# ior7f701503 register map
Registers are 8-bit, access not given, no defined reset value unless marked. A register's access mark holds for its fields unless they carry their own. Addresses are absolute; registers are grouped by the start of their names; [hi:lo] are bit positions; {n}, {i} and the like mark numbered series.

## SFR (part 1 of 4)
0x10020004 FLXA0FROC 32-bit
0x10020004 FLXA0FROCL 16-bit
0x10020004 FLXA0FROCLL
0x10020006 FLXA0FROCH 16-bit
0x10020006 FLXA0FROCHL
0x1002000C FLXA0FROS 32-bit
0x1002000C FLXA0FROSL 16-bit ro
0x1002000C FLXA0FROSLL ro
0x1002000E FLXA0FROSH 16-bit
0x1002000E FLXA0FROSHL
0x1002001C FLXA0FRLCK 32-bit
0x1002001C FLXA0FRLCKL 16-bit
0x1002001C FLXA0FRLCKLL
0x1002001D FLXA0FRLCKLH
0x10020020 FLXA0FREIR 32-bit
0x10020020 FLXA0FREIRL 16-bit
0x10020020 FLXA0FREIRLL
0x10020021 FLXA0FREIRLH
0x10020022 FLXA0FREIRH 16-bit
0x10020022 FLXA0FREIRHL
0x10020023 FLXA0FREIRHH
0x10020024 FLXA0FRSIR 32-bit
0x10020024 FLXA0FRSIRL 16-bit
0x10020024 FLXA0FRSIRLL
0x10020025 FLXA0FRSIRLH
0x10020026 FLXA0FRSIRH 16-bit
0x10020026 FLXA0FRSIRHL
0x10020027 FLXA0FRSIRHH
0x10020028 FLXA0FREILS 32-bit
0x10020028 FLXA0FREILSL 16-bit
0x10020028 FLXA0FREILSLL
0x10020029 FLXA0FREILSLH
0x1002002A FLXA0FREILSH 16-bit
0x1002002A FLXA0FREILSHL
0x1002002B FLXA0FREILSHH
0x1002002C FLXA0FRSILS 32-bit
0x1002002C FLXA0FRSILSL 16-bit
0x1002002C FLXA0FRSILSLL
0x1002002D FLXA0FRSILSLH
0x1002002E FLXA0FRSILSH 16-bit
0x1002002E FLXA0FRSILSHL
0x1002002F FLXA0FRSILSHH
0x10020030 FLXA0FREIES 32-bit
0x10020030 FLXA0FREIESL 16-bit
0x10020030 FLXA0FREIESLL
0x10020031 FLXA0FREIESLH
0x10020032 FLXA0FREIESH 16-bit
0x10020032 FLXA0FREIESHL
0x10020033 FLXA0FREIESHH
0x10020034 FLXA0FREIER 32-bit
0x10020034 FLXA0FREIERL 16-bit
0x10020034 FLXA0FREIERLL
0x10020035 FLXA0FREIERLH
0x10020036 FLXA0FREIERH 16-bit
0x10020036 FLXA0FREIERHL
0x10020037 FLXA0FREIERHH
0x10020038 FLXA0FRSIES 32-bit
0x10020038 FLXA0FRSIESL 16-bit
0x10020038 FLXA0FRSIESLL
0x10020039 FLXA0FRSIESLH
0x1002003A FLXA0FRSIESH 16-bit
0x1002003A FLXA0FRSIESHL
0x1002003B FLXA0FRSIESHH
0x1002003C FLXA0FRSIER 32-bit
0x1002003C FLXA0FRSIERL 16-bit
0x1002003C FLXA0FRSIERLL
0x1002003D FLXA0FRSIERLH
0x1002003E FLXA0FRSIERH 16-bit
0x1002003E FLXA0FRSIERHL
0x1002003F FLXA0FRSIERHH
0x10020040 FLXA0FRILE 32-bit
0x10020040 FLXA0FRILEL 16-bit
0x10020040 FLXA0FRILELL
0x10020044 FLXA0FRT0C 32-bit
0x10020044 FLXA0FRT0CL 16-bit
0x10020044 FLXA0FRT0CLL
0x10020045 FLXA0FRT0CLH
0x10020046 FLXA0FRT0CH 16-bit
0x10020046 FLXA0FRT0CHL
0x10020047 FLXA0FRT0CHH
0x10020048 FLXA0FRT1C 32-bit
0x10020048 FLXA0FRT1CL 16-bit
0x10020048 FLXA0FRT1CLL
0x1002004A FLXA0FRT1CH 16-bit
0x1002004A FLXA0FRT1CHL
0x1002004B FLXA0FRT1CHH
0x1002004C FLXA0FRSTPW1 32-bit
0x1002004C FLXA0FRSTPW1L 16-bit
0x1002004C FLXA0FRSTPW1LL
0x1002004D FLXA0FRSTPW1LH ro
0x1002004E FLXA0FRSTPW1H 16-bit ro
0x1002004E FLXA0FRSTPW1HL ro
0x1002004F FLXA0FRSTPW1HH ro
0x10020050 FLXA0FRSTPW2 32-bit ro
0x10020050 FLXA0FRSTPW2L 16-bit ro
0x10020050 FLXA0FRSTPW2LL ro
0x10020051 FLXA0FRSTPW2LH ro
0x10020052 FLXA0FRSTPW2H 16-bit ro
0x10020052 FLXA0FRSTPW2HL ro
0x10020053 FLXA0FRSTPW2HH ro
{0x1002007C+4i} FLXA0FRSUCC{i} 32-bit (i=1..3)
{0x1002007C+4i} FLXA0FRSUCC{i}L 16-bit (i=1..3)
{0x1002007C+4i} FLXA0FRSUCC{i}LL (i=1..3)
0x10020081 FLXA0FRSUCC1LH
0x10020082 FLXA0FRSUCC1H 16-bit
0x10020082 FLXA0FRSUCC1HL
0x10020083 FLXA0FRSUCC1HH
0x10020085 FLXA0FRSUCC2LH
0x10020086 FLXA0FRSUCC2H 16-bit
0x10020086 FLXA0FRSUCC2HL
0x10020087 FLXA0FRSUCC2HH
0x1002008C FLXA0FRNEMC 32-bit
0x1002008C FLXA0FRNEMCL 16-bit
0x1002008C FLXA0FRNEMCLL
0x10020090 FLXA0FRPRTC1 32-bit
0x10020090 FLXA0FRPRTC1L 16-bit
0x10020090 FLXA0FRPRTC1LL
0x10020091 FLXA0FRPRTC1LH
0x10020092 FLXA0FRPRTC1H 16-bit
0x10020092 FLXA0FRPRTC1HL
0x10020093 FLXA0FRPRTC1HH
0x10020094 FLXA0FRPRTC2 32-bit
0x10020094 FLXA0FRPRTC2L 16-bit
0x10020094 FLXA0FRPRTC2LL
0x10020095 FLXA0FRPRTC2LH
0x10020096 FLXA0FRPRTC2H 16-bit
0x10020096 FLXA0FRPRTC2HL
0x10020097 FLXA0FRPRTC2HH
0x10020098 FLXA0FRMHDC 32-bit
0x10020098 FLXA0FRMHDCL 16-bit
0x10020098 FLXA0FRMHDCLL
0x1002009A FLXA0FRMHDCH 16-bit
0x1002009A FLXA0FRMHDCHL
0x1002009B FLXA0FRMHDCHH
{0x1002009C+4i} FLXA0FRGTUC{i} 32-bit (i=1..11)
{0x1002009C+4i} FLXA0FRGTUC{i}L 16-bit (i=1..11)
{0x1002009C+4i} FLXA0FRGTUC{i}LL (i=1..11)
{0x1002009D+4i} FLXA0FRGTUC{i}LH (i=1..7)
{0x1002009E+4i} FLXA0FRGTUC{i}H 16-bit (i=1..11)
{0x1002009E+4i} FLXA0FRGTUC{i}HL (i=1..11)
{0x1002009F+4i} FLXA0FRGTUC{i}HH (i=3..8)
{0x1002009D+4i} FLXA0FRGTUC{i}LH (i=9..11)
0x100200C7 FLXA0FRGTUC10HH
0x100200CB FLXA0FRGTUC11HH
0x10020100 FLXA0FRCCSV 32-bit ro
0x10020100 FLXA0FRCCSVL 16-bit ro
0x10020100 FLXA0FRCCSVLL ro
0x10020101 FLXA0FRCCSVLH ro
0x10020102 FLXA0FRCCSVH 16-bit ro
0x10020102 FLXA0FRCCSVHL ro
0x10020103 FLXA0FRCCSVHH ro
0x10020104 FLXA0FRCCEV 32-bit ro
0x10020104 FLXA0FRCCEVL 16-bit ro
0x10020104 FLXA0FRCCEVLL ro
0x10020105 FLXA0FRCCEVLH ro
0x10020110 FLXA0FRSCV 32-bit ro
0x10020110 FLXA0FRSCVL 16-bit ro
0x10020110 FLXA0FRSCVLL ro
0x10020111 FLXA0FRSCVLH ro
0x10020112 FLXA0FRSCVH 16-bit ro
0x10020112 FLXA0FRSCVHL ro
0x10020113 FLXA0FRSCVHH ro
0x10020114 FLXA0FRMTCCV 32-bit ro
0x10020114 FLXA0FRMTCCVL 16-bit ro
0x10020114 FLXA0FRMTCCVLL ro
0x10020115 FLXA0FRMTCCVLH ro
0x10020116 FLXA0FRMTCCVH 16-bit ro
0x10020116 FLXA0FRMTCCVHL ro
0x10020118 FLXA0FRRCV 32-bit ro
0x10020118 FLXA0FRRCVL 16-bit ro
0x10020118 FLXA0FRRCVLL ro
0x10020119 FLXA0FRRCVLH ro
0x1002011C FLXA0FROCV 32-bit ro
0x1002011C FLXA0FROCVL 16-bit ro
0x1002011C FLXA0FROCVLL ro
0x1002011D FLXA0FROCVLH ro
0x1002011E FLXA0FROCVH 16-bit ro
0x1002011E FLXA0FROCVHL ro
0x10020120 FLXA0FRSFS 32-bit ro
0x10020120 FLXA0FRSFSL 16-bit ro
0x10020120 FLXA0FRSFSLL ro
0x10020121 FLXA0FRSFSLH ro
0x10020122 FLXA0FRSFSH 16-bit ro
0x10020122 FLXA0FRSFSHL ro
0x10020124 FLXA0FRSWNIT 32-bit ro
0x10020124 FLXA0FRSWNITL 16-bit ro
0x10020124 FLXA0FRSWNITLL ro
0x10020125 FLXA0FRSWNITLH ro
0x10020128 FLXA0FRACS 32-bit
0x10020128 FLXA0FRACSL 16-bit
0x10020128 FLXA0FRACSLL
0x10020129 FLXA0FRACSLH
{0x1002012C+4i} FLXA0FRESID{i} 32-bit ro (i=1..15)
{0x1002012C+4i} FLXA0FRESID{i}L 16-bit ro (i=1..15)
{0x1002012C+4i} FLXA0FRESID{i}LL ro (i=1..15)
{0x1002012D+4i} FLXA0FRESID{i}LH ro (i=1..15)
{0x1002016C+4i} FLXA0FROSID{i} 32-bit ro (i=1..15)
{0x1002016C+4i} FLXA0FROSID{i}L 16-bit ro (i=1..15)
{0x1002016C+4i} FLXA0FROSID{i}LL ro (i=1..15)
{0x1002016D+4i} FLXA0FROSID{i}LH ro (i=1..15)
{0x100201AC+4i} FLXA0FRNMV{i} 32-bit ro (i=1..3)
{0x100201AC+4i} FLXA0FRNMV{i}L 16-bit ro (i=1..3)
{0x100201AC+4i} FLXA0FRNMV{i}LL ro (i=1..3)
{0x100201AD+4i} FLXA0FRNMV{i}LH ro (i=1..3)
{0x100201AE+4i} FLXA0FRNMV{i}H 16-bit ro (i=1..3)
{0x100201AE+4i} FLXA0FRNMV{i}HL ro (i=1..3)
{0x100201AF+4i} FLXA0FRNMV{i}HH ro (i=1..3)
0x10020300 FLXA0FRMRC 32-bit
0x10020300 FLXA0FRMRCL 16-bit
0x10020300 FLXA0FRMRCLL
0x10020301 FLXA0FRMRCLH
0x10020302 FLXA0FRMRCH 16-bit
0x10020302 FLXA0FRMRCHL
0x10020303 FLXA0FRMRCHH
0x10020304 FLXA0FRFRF 32-bit
0x10020304 FLXA0FRFRFL 16-bit
0x10020304 FLXA0FRFRFLL
0x10020305 FLXA0FRFRFLH
0x10020306 FLXA0FRFRFH 16-bit
0x10020306 FLXA0FRFRFHL
0x10020307 FLXA0FRFRFHH
0x10020308 FLXA0FRFRFM 32-bit
0x10020308 FLXA0FRFRFML 16-bit
0x10020308 FLXA0FRFRFMLL
0x10020309 FLXA0FRFRFMLH
0x1002030C FLXA0FRFCL 32-bit
0x1002030C FLXA0FRFCLL 16-bit
0x1002030C FLXA0FRFCLLL
0x10020310 FLXA0FRMHDS 32-bit
0x10020310 FLXA0FRMHDSL 16-bit
0x10020310 FLXA0FRMHDSLL
0x10020311 FLXA0FRMHDSLH ro
0x10020312 FLXA0FRMHDSH 16-bit ro
0x10020312 FLXA0FRMHDSHL ro
0x10020313 FLXA0FRMHDSHH ro
0x10020314 FLXA0FRLDTS 32-bit ro
0x10020314 FLXA0FRLDTSL 16-bit ro
0x10020314 FLXA0FRLDTSLL ro
0x10020315 FLXA0FRLDTSLH ro
0x10020316 FLXA0FRLDTSH 16-bit ro
0x10020316 FLXA0FRLDTSHL ro
0x10020317 FLXA0FRLDTSHH ro
0x10020318 FLXA0FRFSR 32-bit ro
0x10020318 FLXA0FRFSRL 16-bit ro
0x10020318 FLXA0FRFSRLL ro
0x10020319 FLXA0FRFSRLH ro
0x1002031C FLXA0FRMHDF 32-bit
0x1002031C FLXA0FRMHDFL 16-bit
0x1002031C FLXA0FRMHDFLL
0x1002031D FLXA0FRMHDFLH
{0x1002031C+4i} FLXA0FRTXRQ{i} 32-bit ro (i=1..4)
{0x1002031C+4i} FLXA0FRTXRQ{i}L 16-bit ro (i=1..4)
{0x1002031C+4i} FLXA0FRTXRQ{i}LL ro (i=1..4)
{0x1002031D+4i} FLXA0FRTXRQ{i}LH ro (i=1..4)
{0x1002031E+4i} FLXA0FRTXRQ{i}H 16-bit ro (i=1..4)
{0x1002031E+4i} FLXA0FRTXRQ{i}HL ro (i=1..4)
{0x1002031F+4i} FLXA0FRTXRQ{i}HH ro (i=1..4)
{0x1002032C+4i} FLXA0FRNDAT{i} 32-bit ro (i=1..4)
{0x1002032C+4i} FLXA0FRNDAT{i}L 16-bit ro (i=1..4)
{0x1002032C+4i} FLXA0FRNDAT{i}LL ro (i=1..4)
{0x1002032D+4i} FLXA0FRNDAT{i}LH ro (i=1..4)
{0x1002032E+4i} FLXA0FRNDAT{i}H 16-bit ro (i=1..4)
{0x1002032E+4i} FLXA0FRNDAT{i}HL ro (i=1..4)
{0x1002032F+4i} FLXA0FRNDAT{i}HH ro (i=1..4)
{0x1002033C+4i} FLXA0FRMBSC{i} 32-bit ro (i=1..4)
{0x1002033C+4i} FLXA0FRMBSC{i}L 16-bit ro (i=1..4)
{0x1002033C+4i} FLXA0FRMBSC{i}LL ro (i=1..4)
{0x1002033D+4i} FLXA0FRMBSC{i}LH ro (i=1..4)
{0x1002033E+4i} FLXA0FRMBSC{i}H 16-bit ro (i=1..4)
{0x1002033E+4i} FLXA0FRMBSC{i}HL ro (i=1..4)
{0x1002033F+4i} FLXA0FRMBSC{i}HH ro (i=1..4)
{0x100203FC+4i} FLXA0FRWRDS{i} 32-bit (i=1..64)
{0x100203FC+4i} FLXA0FRWRDS{i}L 16-bit (i=1..64)
{0x100203FC+4i} FLXA0FRWRDS{i}LL (i=1..64)
{0x100203FD+4i} FLXA0FRWRDS{i}LH (i=1..64)
{0x100203FE+4i} FLXA0FRWRDS{i}H 16-bit (i=1..64)
{0x100203FE+4i} FLXA0FRWRDS{i}HL (i=1..64)
{0x100203FF+4i} FLXA0FRWRDS{i}HH (i=1..64)
{0x100204FC+4i} FLXA0FRWRHS{i} 32-bit (i=1..3)
{0x100204FC+4i} FLXA0FRWRHS{i}L 16-bit (i=1..3)
{0x100204FC+4i} FLXA0FRWRHS{i}LL (i=1..3)
{0x100204FD+4i} FLXA0FRWRHS{i}LH (i=1..3)
0x10020502 FLXA0FRWRHS1H 16-bit
0x10020502 FLXA0FRWRHS1HL
0x10020503 FLXA0FRWRHS1HH
0x10020506 FLXA0FRWRHS2H 16-bit
0x10020506 FLXA0FRWRHS2HL
0x10020510 FLXA0FRIBCM 32-bit
0x10020510 FLXA0FRIBCML 16-bit
0x10020510 FLXA0FRIBCMLL
0x10020512 FLXA0FRIBCMH 16-bit ro
0x10020512 FLXA0FRIBCMHL ro
0x10020514 FLXA0FRIBCR 32-bit
0x10020514 FLXA0FRIBCRL 16-bit
0x10020514 FLXA0FRIBCRLL
0x10020515 FLXA0FRIBCRLH ro
0x10020516 FLXA0FRIBCRH 16-bit ro
0x10020516 FLXA0FRIBCRHL ro
0x10020517 FLXA0FRIBCRHH ro
{0x100205FC+4i} FLXA0FRRDDS{i} 32-bit ro (i=1..64)
{0x100205FC+4i} FLXA0FRRDDS{i}L 16-bit ro (i=1..64)
{0x100205FC+4i} FLXA0FRRDDS{i}LL ro (i=1..64)
{0x100205FD+4i} FLXA0FRRDDS{i}LH ro (i=1..64)
{0x100205FE+4i} FLXA0FRRDDS{i}H 16-bit ro (i=1..64)
{0x100205FE+4i} FLXA0FRRDDS{i}HL ro (i=1..64)
{0x100205FF+4i} FLXA0FRRDDS{i}HH ro (i=1..64)
{0x100206FC+4i} FLXA0FRRDHS{i} 32-bit ro (i=1..3)
{0x100206FC+4i} FLXA0FRRDHS{i}L 16-bit ro (i=1..3)
{0x100206FC+4i} FLXA0FRRDHS{i}LL ro (i=1..3)
{0x100206FD+4i} FLXA0FRRDHS{i}LH ro (i=1..3)
{0x100206FE+4i} FLXA0FRRDHS{i}H 16-bit ro (i=1..3)
{0x100206FE+4i} FLXA0FRRDHS{i}HL ro (i=1..3)
{0x100206FF+4i} FLXA0FRRDHS{i}HH ro (i=1..3)
0x1002070C FLXA0FRMBS 32-bit ro
0x1002070C FLXA0FRMBSL 16-bit ro
0x1002070C FLXA0FRMBSLL ro
0x1002070D FLXA0FRMBSLH ro
0x1002070E FLXA0FRMBSH 16-bit ro
0x1002070E FLXA0FRMBSHL ro
0x1002070F FLXA0FRMBSHH ro
0x10020710 FLXA0FROBCM 32-bit
0x10020710 FLXA0FROBCML 16-bit
0x10020710 FLXA0FROBCMLL
0x10020712 FLXA0FROBCMH 16-bit ro
0x10020712 FLXA0FROBCMHL ro
0x10020714 FLXA0FROBCR 32-bit
0x10020714 FLXA0FROBCRL 16-bit
0x10020714 FLXA0FROBCRLL
0x10020715 FLXA0FROBCRLH
0x10020716 FLXA0FROBCRH 16-bit ro
0x10020716 FLXA0FROBCRHL ro
0x10020800 FLXA0FRITC 32-bit
0x10020800 FLXA0FRITCL 16-bit
0x10020800 FLXA0FRITCLL
0x10020801 FLXA0FRITCLH
0x10020802 FLXA0FRITCH 16-bit
0x10020802 FLXA0FRITCHL
0x10020804 FLXA0FROTC 32-bit
0x10020804 FLXA0FROTCL 16-bit
0x10020804 FLXA0FROTCLL
0x10020805 FLXA0FROTCLH
0x10020806 FLXA0FROTCH 16-bit
0x10020806 FLXA0FROTCHL
0x10020808 FLXA0FRIBA 32-bit
0x10020808 FLXA0FRIBAL 16-bit
0x10020808 FLXA0FRIBALL
0x10020809 FLXA0FRIBALH
0x1002080A FLXA0FRIBAH 16-bit
0x1002080A FLXA0FRIBAHL
0x1002080B FLXA0FRIBAHH
0x1002080C FLXA0FRFBA 32-bit
0x1002080C FLXA0FRFBAL 16-bit
0x1002080C FLXA0FRFBALL
0x1002080D FLXA0FRFBALH
0x1002080E FLXA0FRFBAH 16-bit
0x1002080E FLXA0FRFBAHL
0x1002080F FLXA0FRFBAHH
0x10020810 FLXA0FROBA 32-bit
0x10020810 FLXA0FROBAL 16-bit
0x10020810 FLXA0FROBALL
0x10020811 FLXA0FROBALH
0x10020812 FLXA0FROBAH 16-bit
0x10020812 FLXA0FROBAHL
0x10020813 FLXA0FROBAHH
0x10020814 FLXA0FRIQC 32-bit wo
0x10020814 FLXA0FRIQCL 16-bit wo
0x10020814 FLXA0FRIQCLL wo
0x10020818 FLXA0FRUIR 32-bit
0x10020818 FLXA0FRUIRL 16-bit
0x10020818 FLXA0FRUIRLL
0x1002081C FLXA0FRUOR 32-bit
0x1002081C FLXA0FRUORL 16-bit
0x1002081C FLXA0FRUORLL
0x1002081D FLXA0FRUORLH
0x10020820 FLXA0FRITS 32-bit
0x10020820 FLXA0FRITSL 16-bit
0x10020820 FLXA0FRITSLL ro
0x10020821 FLXA0FRITSLH
0x10020822 FLXA0FRITSH 16-bit ro
0x10020822 FLXA0FRITSHL ro
0x10020823 FLXA0FRITSHH ro
0x10020824 FLXA0FROTS 32-bit
0x10020824 FLXA0FROTSL 16-bit
0x10020824 FLXA0FROTSLL ro
0x10020825 FLXA0FROTSLH
0x10020826 FLXA0FROTSH 16-bit ro
0x10020826 FLXA0FROTSHL ro
0x10020827 FLXA0FROTSHH ro
0x10020828 FLXA0FRAES 32-bit
0x10020828 FLXA0FRAESL 16-bit
0x10020828 FLXA0FRAESLL ro
0x10020829 FLXA0FRAESLH
0x1002082C FLXA0FRAEA 32-bit ro
0x1002082C FLXA0FRAEAL 16-bit ro
0x1002082C FLXA0FRAEALL ro
0x1002082D FLXA0FRAEALH ro
0x1002082E FLXA0FRAEAH 16-bit ro
0x1002082E FLXA0FRAEAHL ro
0x1002082F FLXA0FRAEAHH ro
{0x10020830+4i} FLXA0FRDA{i} 32-bit (i=0..3)
{0x10020830+4i} FLXA0FRDA{i}L 16-bit (i=0..3)
{0x10020830+4i} FLXA0FRDA{i}LL (i=0..3)
{0x10020831+4i} FLXA0FRDA{i}LH (i=0..3)
{0x10020832+4i} FLXA0FRDA{i}H 16-bit (i=0..3)
{0x10020832+4i} FLXA0FRDA{i}HL (i=0..3)
{0x10020833+4i} FLXA0FRDA{i}HH (i=0..3)
0x10020840 FLXA0FRAHBC 32-bit
0x10020840 FLXA0FRAHBCL 16-bit
0x10020840 FLXA0FRAHBCLL
0x10020844 FLXA0FRT2C 32-bit
0x10020844 FLXA0FRT2CL 16-bit
0x10020844 FLXA0FRT2CLL
0x10020845 FLXA0FRT2CLH
0x10020846 FLXA0FRT2CH 16-bit
0x10020846 FLXA0FRT2CHL
0x10020847 FLXA0FRT2CHH
0x10030002 MEMC0DEC 16-bit
0x10030008 MEMC0DWC 16-bit
0x1003000C MEMC0DHC 16-bit
0x1003000E MEMC0DSC 16-bit
0x10030010 MEMC0AWC 16-bit
0x10030014 MEMC0ICC 16-bit
0x1003001A MEMC0EWC 16-bit
0xFFA00000 FLMDCNT 32-bit
0xFFA00004 FLMDPCMD 32-bit wo
0xFFA00008 FLMDPS 32-bit ro
{0xFFA08000+4i} SELFID{i} 32-bit (i=0..3)
0xFFA08010 SELFIDST 32-bit ro
0xFFA10000 FACIFPMON ro
0xFFA10010 FACIFASTAT
0xFFA10014 FACIFAEINT
0xFFA10020 FACIFAREASELC 16-bit
0xFFA10030 FACIFSADDR 32-bit
0xFFA10034 FACIFEADDR 32-bit
0xFFA10054 FACIFCURAME 16-bit
0xFFA10080 FACIFSTATR 32-bit ro
0xFFA10084 FACIFENTRYR 16-bit
0xFFA10088 FACIFPROTR 16-bit
0xFFA1008C FACIFSUINITR 16-bit
0xFFA10090 FACIFLKSTAT ro
0xFFA10094 FACIFRFSTEADR 32-bit ro
0xFFA100A0 FACIFCMDR 16-bit ro
0xFFA100B0 FACIFRAMECCR 16-bit
0xFFA100C0 FACIFPESTAT 16-bit ro
0xFFA100D0 FACIFBCCNT
0xFFA100D4 FACIFBCSTAT ro
0xFFA100D8 FACIFPSADDR 32-bit ro
0xFFA100E0 FACIFCPSR 16-bit
0xFFA100E4 FACIFPCKAR 16-bit
0xFFA10100 FACIFECCEMON 16-bit ro
0xFFA10104 FACIFECCTMD 16-bit
0xFFA10108 FACIFDMYECC 16-bit
0xFFC00000 WDTNMIF 32-bit ro
0xFFC00008 WDTNMIFC 32-bit wo
0xFFC00100 FEINTF 32-bit ro
0xFFC00104 FEINTFMSK 32-bit
0xFFC00108 FEINTFC 32-bit wo
{0xFFC10000+4i} P{i} 16-bit (i=0..2)
{0xFFC10000+4i} P{i} 16-bit (i=8..12)
0xFFC10048 P18 16-bit
0xFFC10050 P20 16-bit
0xFFC100C8 AP0 16-bit
0xFFC100CC AP1 16-bit
{0xFFC10100+4i} PSR{i} 32-bit (i=0..2)
{0xFFC10100+4i} PSR{i} 32-bit (i=8..12)
0xFFC10148 PSR18 32-bit
0xFFC10150 PSR20 32-bit
0xFFC101C8 APSR0 32-bit
0xFFC101CC APSR1 32-bit
{0xFFC10200+4i} PPR{i} 16-bit ro (i=0..2)
{0xFFC10200+4i} PPR{i} 16-bit ro (i=8..12)
0xFFC10248 PPR18 16-bit ro
0xFFC10250 PPR20 16-bit ro
0xFFC102C8 APPR0 16-bit ro
0xFFC102CC APPR1 16-bit ro
0xFFC102F0 IPPR0 16-bit ro
{0xFFC10300+4i} PM{i} 16-bit (i=0..2)
{0xFFC10300+4i} PM{i} 16-bit (i=8..12)
0xFFC10348 PM18 16-bit
0xFFC10350 PM20 16-bit
0xFFC103C8 APM0 16-bit
0xFFC103CC APM1 16-bit
{0xFFC10400+4i} PMC{i} 16-bit (i=0..2)
{0xFFC10400+4i} PMC{i} 16-bit (i=8..12)
0xFFC10448 PMC18 16-bit
0xFFC10450 PMC20 16-bit
{0xFFC10500+4i} PFC{i} 16-bit (i=0..2)
{0xFFC10500+4i} PFC{i} 16-bit (i=8..12)
0xFFC10548 PFC18 16-bit
0xFFC10550 PFC20 16-bit
0xFFC10600 PFCE0 16-bit
{0xFFC10600+4i} PFCE{i} 16-bit (i=8..12)
0xFFC10648 PFCE18 16-bit
0xFFC10650 PFCE20 16-bit
{0xFFC10700+4i} PNOT{i} 16-bit wo (i=0..2)
{0xFFC10700+4i} PNOT{i} 16-bit wo (i=8..12)
0xFFC10748 PNOT18 16-bit wo
0xFFC10750 PNOT20 16-bit wo
0xFFC107C8 APNOT0 16-bit wo
0xFFC107CC APNOT1 16-bit wo
{0xFFC10800+4i} PMSR{i} 32-bit (i=0..2)
{0xFFC10800+4i} PMSR{i} 32-bit (i=8..12)
0xFFC10848 PMSR18 32-bit
0xFFC10850 PMSR20 32-bit
0xFFC108C8 APMSR0 32-bit
0xFFC108CC APMSR1 32-bit
{0xFFC10900+4i} PMCSR{i} 32-bit (i=0..2)
{0xFFC10900+4i} PMCSR{i} 32-bit (i=8..12)
0xFFC10948 PMCSR18 32-bit
0xFFC10950 PMCSR20 32-bit
0xFFC10A00 PFCAE0 16-bit
0xFFC10A28 PFCAE10 16-bit
0xFFC10A2C PFCAE11 16-bit
{0xFFC14000+4i} PIBC{i} 16-bit (i=0..2)
{0xFFC14000+4i} PIBC{i} 16-bit (i=8..12)
0xFFC14048 PIBC18 16-bit
0xFFC14050 PIBC20 16-bit
0xFFC140C8 APIBC0 16-bit
0xFFC140CC APIBC1 16-bit
0xFFC140F0 IPIBC0 16-bit
{0xFFC14100+4i} PBDC{i} 16-bit (i=0..2)
{0xFFC14100+4i} PBDC{i} 16-bit (i=8..12)
0xFFC14148 PBDC18 16-bit
0xFFC14150 PBDC20 16-bit
0xFFC141C8 APBDC0 16-bit
0xFFC141CC APBDC1 16-bit
0xFFC14200 PIPC0 16-bit
{0xFFC14200+4i} PIPC{i} 16-bit (i=10..12)
0xFFC14250 PIPC20 16-bit
{0xFFC14300+4i} PU{i} 16-bit (i=0..2)
{0xFFC14300+4i} PU{i} 16-bit (i=8..12)
0xFFC14348 PU18 16-bit
0xFFC14350 PU20 16-bit
0xFFC14400 PD0 16-bit
{0xFFC14400+4i} PD{i} 16-bit (i=8..11)
{0xFFC14500+4i} PODC{i} 32-bit (i=0..2)
{0xFFC14500+4i} PODC{i} 32-bit (i=8..12)
0xFFC14548 PODC18 32-bit
0xFFC14550 PODC20 32-bit
0xFFC14600 PDSC0 32-bit
{0xFFC14600+4i} PDSC{i} 32-bit (i=10..12)
0xFFC14648 PDSC18 32-bit
0xFFC14650 PDSC20 32-bit
{0xFFC14700+4i} PIS{i} 16-bit (i=0..2)
{0xFFC14700+4i} PIS{i} 16-bit (i=10..12)
0xFFC14750 PIS20 16-bit
{0xFFC14A00+4i} PISA{i} 16-bit (i=10..12)
0xFFC14A48 PISA18 16-bit
{0xFFC14B00+4i} PPROTS{i} 32-bit ro (i=0..2)
{0xFFC14B00+4i} PPROTS{i} 32-bit ro (i=8..12)
0xFFC14B48 PPROTS18 32-bit ro
0xFFC14B50 PPROTS20 32-bit ro
{0xFFC14C00+4i} PPCMD{i} 32-bit wo (i=0..2)
{0xFFC14C00+4i} PPCMD{i} 32-bit wo (i=8..12)
0xFFC14C48 PPCMD18 32-bit wo
0xFFC14C50 PPCMD20 32-bit wo
0xFFC20000 JP0
0xFFC20010 JPSR0 32-bit
0xFFC20020 JPPR0 ro
0xFFC20030 JPM0
0xFFC20040 JPMC0
0xFFC20050 JPFC0
0xFFC20070 JPNOT0 wo
0xFFC20080 JPMSR0 32-bit
0xFFC20090 JPMCSR0 32-bit
0xFFC20400 JPIBC0
0xFFC20410 JPBDC0
0xFFC20430 JPU0
0xFFC20440 JPD0
0xFFC20450 JPODC0 32-bit
0xFFC204B0 JPPROTS0 32-bit ro
0xFFC204C0 JPPCMD0 32-bit wo
0xFFC30000 DNFATAUD0ICTL
0xFFC30004 DNFATAUD0IEN 16-bit
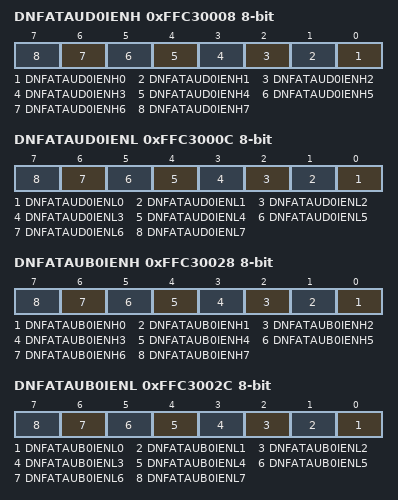
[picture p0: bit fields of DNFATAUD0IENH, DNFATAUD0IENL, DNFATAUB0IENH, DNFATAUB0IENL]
0xFFC30008 DNFATAUD0IENH
  [n] DNFATAUD0IENH{n} (n=0..7)
0xFFC3000C DNFATAUD0IENL
  [n] DNFATAUD0IENL{n} (n=0..7)
0xFFC30020 DNFATAUB0ICTL
0xFFC30024 DNFATAUB0IEN 16-bit
0xFFC30028 DNFATAUB0IENH
  [n] DNFATAUB0IENH{n} (n=0..7)
0xFFC3002C DNFATAUB0IENL
  [n] DNFATAUB0IENL{n} (n=0..7)
0xFFC30040 DNFATAUB1ICTL
0xFFC30044 DNFATAUB1IEN 16-bit
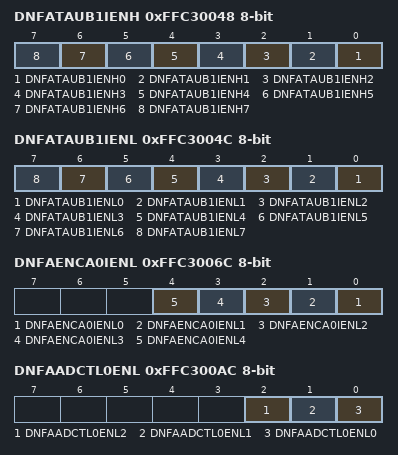
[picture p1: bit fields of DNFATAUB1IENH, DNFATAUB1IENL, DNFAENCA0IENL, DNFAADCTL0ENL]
0xFFC30048 DNFATAUB1IENH
  [n] DNFATAUB1IENH{n} (n=0..7)
0xFFC3004C DNFATAUB1IENL
  [n] DNFATAUB1IENL{n} (n=0..7)
0xFFC30060 DNFAENCA0ICTL
0xFFC30064 DNFAENCA0IEN 16-bit
0xFFC3006C DNFAENCA0IENL
  [n] DNFAENCA0IENL{n} (n=0..4)
0xFFC300A0 DNFAADCTL0CTL
0xFFC300A4 DNFAADCTL0EN 16-bit
0xFFC300AC DNFAADCTL0ENL
  [2] DNFAADCTL0ENL2, [1] DNFAADCTL0ENL1, [0] DNFAADCTL0ENL0
0xFFC300C0 DNFAADCTL1CTL
0xFFC300C4 DNFAADCTL1EN 16-bit
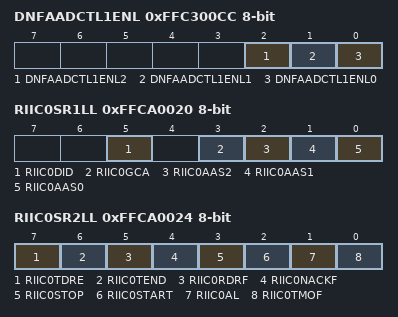
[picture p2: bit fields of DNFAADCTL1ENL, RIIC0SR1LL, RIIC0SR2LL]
0xFFC300CC DNFAADCTL1ENL
  [2] DNFAADCTL1ENL2, [1] DNFAADCTL1ENL1, [0] DNFAADCTL1ENL0
{0xFFC40000+4i} FSGD00PROT{i} 32-bit (i=0..13)
{0xFFC40000+4i} FSGD00PROT{i}L 16-bit (i=0..13)
{0xFFC40000+4i} FSGD00PROT{i}LL (i=0..13)
{0xFFC40001+4i} FSGD00PROT{i}LH (i=0..13)
{0xFFC40002+4i} FSGD00PROT{i}H 16-bit (i=0..13)
{0xFFC40002+4i} FSGD00PROT{i}HL (i=0..13)
{0xFFC40003+4i} FSGD00PROT{i}HH (i=0..13)
0xFFC40040 ERRSLV00CTL 32-bit wo
0xFFC40040 ERRSLV00CTLL 16-bit wo
0xFFC40040 ERRSLV00CTLLL wo
0xFFC40044 ERRSLV00STAT 32-bit ro
0xFFC40044 ERRSLV00STATL 16-bit ro
0xFFC40044 ERRSLV00STATLL ro
0xFFC4004C ERRSLV00TYPE 32-bit ro
0xFFC4004C ERRSLV00TYPEL 16-bit ro
{0xFFC40100+4i} FSGD01PROT{i} 32-bit (i=0..8)
{0xFFC40100+4i} FSGD01PROT{i}L 16-bit (i=0..8)
{0xFFC40100+4i} FSGD01PROT{i}LL (i=0..8)
{0xFFC40101+4i} FSGD01PROT{i}LH (i=0..8)
{0xFFC40102+4i} FSGD01PROT{i}H 16-bit (i=0..8)
{0xFFC40102+4i} FSGD01PROT{i}HL (i=0..8)
{0xFFC40103+4i} FSGD01PROT{i}HH (i=0..8)
0xFFC40140 ERRSLV01CTL 32-bit wo
0xFFC40140 ERRSLV01CTLL 16-bit wo
0xFFC40140 ERRSLV01CTLLL wo
0xFFC40144 ERRSLV01STAT 32-bit ro
0xFFC40144 ERRSLV01STATL 16-bit ro
0xFFC40144 ERRSLV01STATLL ro
0xFFC4014C ERRSLV01TYPE 32-bit ro
0xFFC4014C ERRSLV01TYPEL 16-bit ro
{0xFFC49000+0x10*i} MGDGRPROT{i} 32-bit (i=0..3)
{0xFFC49000+0x10*i} MGDGRPROT{i}L 16-bit (i=0..3)
{0xFFC49000+0x10*i} MGDGRPROT{i}LL (i=0..3)
{0xFFC49001+0x10*i} MGDGRPROT{i}LH (i=0..3)
{0xFFC49002+0x10*i} MGDGRPROT{i}H 16-bit (i=0..3)
{0xFFC49002+0x10*i} MGDGRPROT{i}HL (i=0..3)
{0xFFC49003+0x10*i} MGDGRPROT{i}HH (i=0..3)
{0xFFC49004+0x10*i} MGDGRBAD{i} 32-bit (i=0..3)
{0xFFC49004+0x10*i} MGDGRBAD{i}L 16-bit (i=0..3)
{0xFFC49005+0x10*i} MGDGRBAD{i}LH (i=0..3)
{0xFFC49006+0x10*i} MGDGRBAD{i}H 16-bit (i=0..3)
{0xFFC49006+0x10*i} MGDGRBAD{i}HL (i=0..3)
{0xFFC49008+0x10*i} MGDGRADV{i} 32-bit (i=0..3)
{0xFFC49008+0x10*i} MGDGRADV{i}L 16-bit (i=0..3)
{0xFFC49009+0x10*i} MGDGRADV{i}LH (i=0..3)
{0xFFC4900A+0x10*i} MGDGRADV{i}H 16-bit (i=0..3)
{0xFFC4900A+0x10*i} MGDGRADV{i}HL (i=0..3)
0xFFC59008 FCUFAREA 32-bit
0xFFC59810 EEPRDCYCL
0xFFC62A00 DFECCCTL 16-bit
0xFFC62A04 DFERSTR 32-bit ro
0xFFC62A08 DFERSTC wo
0xFFC62A14 DFERRINT
0xFFC62A1C DFTSTCTL 16-bit
0xFFC64004 GRTSTCTL 32-bit
0xFFC64004 GRTSTCTLL 16-bit
{0xFFC64008+4i} GRTDATBF{i} 32-bit ro (i=0..3)
0xFFC64018 GRDECINBF0 32-bit
0xFFC6401C GRDECINBF1 32-bit
{0xFFC70000+0x10*i} ECCCSIH{i}CTL 16-bit (i=0..3)
{0xFFC70004+0x10*i} ECCCSIH{i}TMC 16-bit (i=0..3)
{0xFFC70008+0x10*i} ECCCSIH{i}TRC 32-bit (i=0..3)
{0xFFC70008+0x10*i} ECCCSIH{i}ERDB (i=0..3)
{0xFFC70009+0x10*i} ECCCSIH{i}ECRD ro (i=0..3)
{0xFFC7000A+0x10*i} ECCCSIH{i}HORD ro (i=0..3)
{0xFFC7000B+0x10*i} ECCCSIH{i}SYND ro (i=0..3)
{0xFFC7000C+0x10*i} ECCCSIH{i}TED 32-bit (i=0..3)
0xFFC71000 ECCRCAN0CTL 16-bit
0xFFC71004 ECCRCAN0TMC 16-bit
0xFFC71008 ECCRCAN0TRC 32-bit
0xFFC71008 ECCRCAN0ERDB
0xFFC71009 ECCRCAN0ECRD ro
0xFFC7100A ECCRCAN0HORD ro
0xFFC7100B ECCRCAN0SYND ro
0xFFC7100C ECCRCAN0TED 32-bit
0xFFC71020 ECCRCAN1CTL 16-bit
0xFFC71024 ECCRCAN1TMC 16-bit
0xFFC71028 ECCRCAN1TRC 32-bit
0xFFC71028 ECCRCAN1ERDB
0xFFC71029 ECCRCAN1ECRD ro
0xFFC7102A ECCRCAN1HORD ro
0xFFC7102B ECCRCAN1SYND ro
0xFFC7102C ECCRCAN1TED 32-bit
0xFFC72000 ECCFLXA0CTL 16-bit
0xFFC72004 ECCFLXA0TMC 16-bit
0xFFC72008 ECCFLXA0TRC 32-bit
0xFFC72008 ECCFLXA0ERDB
0xFFC72009 ECCFLXA0ECRD ro
0xFFC7200A ECCFLXA0HORD ro
0xFFC7200B ECCFLXA0SYND ro
0xFFC7200C ECCFLXA0TED 32-bit
0xFFC73000 ECCFLXA0T0CTL 16-bit
0xFFC73004 ECCFLXA0T0TMC 16-bit
0xFFC73008 ECCFLXA0T0TRC 32-bit
0xFFC73008 ECCFLXA0T0ERDB
0xFFC73009 ECCFLXA0T0ECRD ro
0xFFC7300A ECCFLXA0T0HORD ro
0xFFC7300B ECCFLXA0T0SYND ro
0xFFC7300C ECCFLXA0T0TED 32-bit
0xFFC73010 ECCFLXA0T1CTL 16-bit
0xFFC73014 ECCFLXA0T1TMC 16-bit
0xFFC73018 ECCFLXA0T1TRC 32-bit
0xFFC73018 ECCFLXA0T1ERDB
0xFFC73019 ECCFLXA0T1ECRD ro
0xFFC7301A ECCFLXA0T1HORD ro
0xFFC7301B ECCFLXA0T1SYND ro
0xFFC7301C ECCFLXA0T1TED 32-bit
0xFFC73040 ECCETNB0TXCTL 16-bit
0xFFC73044 ECCETNB0TXTMC 16-bit
0xFFC73048 ECCETNB0TXTRC 32-bit
0xFFC73048 ECCETNB0TXERDB
0xFFC73049 ECCETNB0TXECRD ro
0xFFC7304A ECCETNB0TXHORD ro
0xFFC7304B ECCETNB0TXSYND ro
0xFFC7304C ECCETNB0TXTED 32-bit
0xFFC73050 ECCETNB0RXCTL 16-bit
0xFFC73054 ECCETNB0RXTMC 16-bit
0xFFC73058 ECCETNB0RXTRC 32-bit
0xFFC73058 ECCETNB0RXERDB
0xFFC73059 ECCETNB0RXECRD ro
0xFFC7305A ECCETNB0RXHORD ro
0xFFC7305B ECCETNB0RXSYND ro
0xFFC7305C ECCETNB0RXTED 32-bit
0xFFCA0000 RIIC0CR1 32-bit
0xFFCA0000 RIIC0CR1L 16-bit
0xFFCA0000 RIIC0CR1LL
0xFFCA0001 RIIC0CR1LH
0xFFCA0002 RIIC0CR1H 16-bit
0xFFCA0002 RIIC0CR1HL
0xFFCA0003 RIIC0CR1HH
0xFFCA0004 RIIC0CR2 32-bit
0xFFCA0004 RIIC0CR2L 16-bit
0xFFCA0004 RIIC0CR2LL
0xFFCA0005 RIIC0CR2LH
0xFFCA0006 RIIC0CR2H 16-bit
0xFFCA0006 RIIC0CR2HL
0xFFCA0007 RIIC0CR2HH
{0xFFCA0004+4i} RIIC0MR{i} 32-bit (i=1..3)
{0xFFCA0004+4i} RIIC0MR{i}L 16-bit (i=1..3)
{0xFFCA0004+4i} RIIC0MR{i}LL (i=1..3)
{0xFFCA0005+4i} RIIC0MR{i}LH (i=1..3)
{0xFFCA0006+4i} RIIC0MR{i}H 16-bit (i=1..3)
{0xFFCA0006+4i} RIIC0MR{i}HL (i=1..3)
{0xFFCA0007+4i} RIIC0MR{i}HH (i=1..3)
0xFFCA0014 RIIC0FER 32-bit
0xFFCA0014 RIIC0FERL 16-bit
0xFFCA0014 RIIC0FERLL
0xFFCA0015 RIIC0FERLH
0xFFCA0016 RIIC0FERH 16-bit
0xFFCA0016 RIIC0FERHL
0xFFCA0017 RIIC0FERHH
0xFFCA0018 RIIC0SER 32-bit
0xFFCA0018 RIIC0SERL 16-bit
0xFFCA0018 RIIC0SERLL
0xFFCA0019 RIIC0SERLH
0xFFCA001A RIIC0SERH 16-bit
0xFFCA001A RIIC0SERHL
0xFFCA001B RIIC0SERHH
0xFFCA001C RIIC0IER 32-bit
0xFFCA001C RIIC0IERL 16-bit
0xFFCA001C RIIC0IERLL
0xFFCA001D RIIC0IERLH
0xFFCA001E RIIC0IERH 16-bit
0xFFCA001E RIIC0IERHL
0xFFCA001F RIIC0IERHH
0xFFCA0020 RIIC0SR1 32-bit
0xFFCA0020 RIIC0SR1L 16-bit
0xFFCA0020 RIIC0SR1LL
  [5] RIIC0DID, [3] RIIC0GCA, [2] RIIC0AAS2, [1] RIIC0AAS1, [0] RIIC0AAS0
0xFFCA0021 RIIC0SR1LH
0xFFCA0022 RIIC0SR1H 16-bit
0xFFCA0022 RIIC0SR1HL
0xFFCA0023 RIIC0SR1HH
0xFFCA0024 RIIC0SR2 32-bit
0xFFCA0024 RIIC0SR2L 16-bit
0xFFCA0024 RIIC0SR2LL
  [7] RIIC0TDRE, [6] RIIC0TEND, [5] RIIC0RDRF, [4] RIIC0NACKF, [3] RIIC0STOP, [2] RIIC0START, [1] RIIC0AL, [0] RIIC0TMOF
0xFFCA0025 RIIC0SR2LH
0xFFCA0026 RIIC0SR2H 16-bit
0xFFCA0026 RIIC0SR2HL
0xFFCA0027 RIIC0SR2HH
{0xFFCA0028+4i} RIIC0SAR{i} 32-bit (i=0..2)
{0xFFCA0028+4i} RIIC0SAR{i}L 16-bit (i=0..2)
{0xFFCA0028+4i} RIIC0SAR{i}LL (i=0..2)
{0xFFCA0029+4i} RIIC0SAR{i}LH (i=0..2)
{0xFFCA002A+4i} RIIC0SAR{i}H 16-bit (i=0..2)
{0xFFCA002A+4i} RIIC0SAR{i}HL (i=0..2)
{0xFFCA002B+4i} RIIC0SAR{i}HH (i=0..2)
0xFFCA0034 RIIC0BRL 32-bit
0xFFCA0034 RIIC0BRLL 16-bit
0xFFCA0034 RIIC0BRLLL
0xFFCA0035 RIIC0BRLLH
0xFFCA0036 RIIC0BRLH 16-bit
0xFFCA0036 RIIC0BRLHL
0xFFCA0037 RIIC0BRLHH
0xFFCA0038 RIIC0BRH 32-bit
0xFFCA0038 RIIC0BRHL 16-bit
0xFFCA0038 RIIC0BRHLL
0xFFCA0039 RIIC0BRHLH
0xFFCA003A RIIC0BRHH 16-bit
0xFFCA003A RIIC0BRHHL
0xFFCA003B RIIC0BRHHH
0xFFCA003C RIIC0DRT 32-bit
0xFFCA003C RIIC0DRTL 16-bit
0xFFCA003C RIIC0DRTLL
0xFFCA003D RIIC0DRTLH
0xFFCA003E RIIC0DRTH 16-bit
0xFFCA003E RIIC0DRTHL
0xFFCA003F RIIC0DRTHH
0xFFCA0040 RIIC0DRR 32-bit ro
0xFFCA0040 RIIC0DRRL 16-bit ro
0xFFCA0040 RIIC0DRRLL ro
0xFFCA0041 RIIC0DRRLH ro
0xFFCA0042 RIIC0DRRH 16-bit ro
0xFFCA0042 RIIC0DRRHL ro
0xFFCA0043 RIIC0DRRHH ro
{0xFFCD00CC+4i} SCDSPRDNAME{i} 32-bit (i=1..3)
{0xFFCD8801+0x80*i} RLN{i}GLWBR (i=240..242)
{0xFFCD8802+0x80*i} RLN{i}GLBRP0 (i=240..242)
{0xFFCD8803+0x80*i} RLN{i}GLBRP1 (i=240..242)
{0xFFCD8804+0x80*i} RLN{i}GLSTC (i=240..242)
{0xFFCCD408+0x20*i} RLN{i}L{i-2400}MD (i=2400..2403)
{0xFFCCD409+0x20*i} RLN{i}L{i-2400}BFC (i=2400..2403)
{0xFFCCD40A+0x20*i} RLN{i}L{i-2400}SC (i=2400..2403)
{0xFFCCD40B+0x20*i} RLN{i}L{i-2400}WUP (i=2400..2403)
{0xFFCCD40C+0x20*i} RLN{i}L{i-2400}IE (i=2400..2403)
{0xFFCCD40D+0x20*i} RLN{i}L{i-2400}EDE (i=2400..2403)
{0xFFCCD40E+0x20*i} RLN{i}L{i-2400}CUC (i=2400..2403)
{0xFFCCD410+0x20*i} RLN{i}L{i-2400}TRC (i=2400..2403)
{0xFFCCD411+0x20*i} RLN{i}L{i-2400}MST ro (i=2400..2403)
{0xFFCCD412+0x20*i} RLN{i}L{i-2400}ST (i=2400..2403)
{0xFFCCD413+0x20*i} RLN{i}L{i-2400}EST (i=2400..2403)
{0xFFCCD414+0x20*i} RLN{i}L{i-2400}DFC (i=2400..2403)
{0xFFCCD415+0x20*i} RLN{i}L{i-2400}IDB (i=2400..2403)
{0xFFCCD416+0x20*i} RLN{i}L{i-2400}CBR (i=2400..2403)
{0xFFCE0017+i} RLN2400L0DBR{i} (i=1..8)
{0xFFCE0037+i} RLN2401L1DBR{i} (i=1..8)
{0xFFCE0057+i} RLN2402L2DBR{i} (i=1..8)
{0xFFCE0077+i} RLN2403L3DBR{i} (i=1..8)
{0xFFCCD2C8+0x20*i} RLN{i}L{i-2414}MD (i=2414..2417)
{0xFFCCD2C9+0x20*i} RLN{i}L{i-2414}BFC (i=2414..2417)
{0xFFCCD2CA+0x20*i} RLN{i}L{i-2414}SC (i=2414..2417)
{0xFFCCD2CB+0x20*i} RLN{i}L{i-2414}WUP (i=2414..2417)
{0xFFCCD2CC+0x20*i} RLN{i}L{i-2414}IE (i=2414..2417)
{0xFFCCD2CD+0x20*i} RLN{i}L{i-2414}EDE (i=2414..2417)
{0xFFCCD2CE+0x20*i} RLN{i}L{i-2414}CUC (i=2414..2417)
{0xFFCCD2D0+0x20*i} RLN{i}L{i-2414}TRC (i=2414..2417)
{0xFFCCD2D1+0x20*i} RLN{i}L{i-2414}MST ro (i=2414..2417)
{0xFFCCD2D2+0x20*i} RLN{i}L{i-2414}ST (i=2414..2417)
{0xFFCCD2D3+0x20*i} RLN{i}L{i-2414}EST (i=2414..2417)
{0xFFCCD2D4+0x20*i} RLN{i}L{i-2414}DFC (i=2414..2417)
{0xFFCCD2D5+0x20*i} RLN{i}L{i-2414}IDB (i=2414..2417)
{0xFFCCD2D6+0x20*i} RLN{i}L{i-2414}CBR (i=2414..2417)
{0xFFCE0097+i} RLN2414L0DBR{i} (i=1..8)
{0xFFCE00B7+i} RLN2415L1DBR{i} (i=1..8)
{0xFFCE00D7+i} RLN2416L2DBR{i} (i=1..8)
{0xFFCE00F7+i} RLN2417L3DBR{i} (i=1..8)
0xFFCE0108 RLN2428L0MD
0xFFCE0109 RLN2428L0BFC
0xFFCE010A RLN2428L0SC
0xFFCE010B RLN2428L0WUP
0xFFCE010C RLN2428L0IE
0xFFCE010D RLN2428L0EDE
0xFFCE010E RLN2428L0CUC
0xFFCE0110 RLN2428L0TRC
0xFFCE0111 RLN2428L0MST ro
0xFFCE0112 RLN2428L0ST
0xFFCE0113 RLN2428L0EST
0xFFCE0114 RLN2428L0DFC
0xFFCE0115 RLN2428L0IDB
0xFFCE0116 RLN2428L0CBR
{0xFFCE0117+i} RLN2428L0DBR{i} (i=1..8)
0xFFCE0128 RLN2429L1MD
0xFFCE0129 RLN2429L1BFC
0xFFCE012A RLN2429L1SC
0xFFCE012B RLN2429L1WUP
0xFFCE012C RLN2429L1IE
0xFFCE012D RLN2429L1EDE
0xFFCE012E RLN2429L1CUC
0xFFCE0130 RLN2429L1TRC
0xFFCE0131 RLN2429L1MST ro
0xFFCE0132 RLN2429L1ST
0xFFCE0133 RLN2429L1EST
0xFFCE0134 RLN2429L1DFC
0xFFCE0135 RLN2429L1IDB
0xFFCE0136 RLN2429L1CBR
{0xFFCE0137+i} RLN2429L1DBR{i} (i=1..8)
{0xFFCE1881+0x40*i} RLN{i}LWBR (i=30..35)
{0xFFCE1882+0x40*i} RLN{i}LBRP01 16-bit (i=30..35)
{0xFFCE1882+0x40*i} RLN{i}LBRP0 (i=30..35)
{0xFFCE1883+0x40*i} RLN{i}LBRP1 (i=30..35)
{0xFFCE1884+0x40*i} RLN{i}LSTC (i=30..35)
{0xFFCE1888+0x40*i} RLN{i}LMD (i=30..35)
{0xFFCE1889+0x40*i} RLN{i}LBFC (i=30..35)
{0xFFCE188A+0x40*i} RLN{i}LSC (i=30..35)
{0xFFCE188B+0x40*i} RLN{i}LWUP (i=30..35)
{0xFFCE188C+0x40*i} RLN{i}LIE (i=30..35)
{0xFFCE188D+0x40*i} RLN{i}LEDE (i=30..35)
{0xFFCE188E+0x40*i} RLN{i}LCUC (i=30..35)
{0xFFCE1890+0x40*i} RLN{i}LTRC (i=30..35)
{0xFFCE1891+0x40*i} RLN{i}LMST ro (i=30..35)
{0xFFCE1892+0x40*i} RLN{i}LST (i=30..35)
{0xFFCE1893+0x40*i} RLN{i}LEST (i=30..35)
{0xFFCE1894+0x40*i} RLN{i}LDFC (i=30..35)
{0xFFCE1895+0x40*i} RLN{i}LIDB (i=30..35)
{0xFFCE1896+0x40*i} RLN{i}LCBR (i=30..35)
{0xFFCE1897+0x40*i} RLN{i}LUDB0 (i=30..35)
{0xFFCE2017+i} RLN30LDBR{i} (i=1..8)
{0xFFCE18A0+0x40*i} RLN{i}LUOER (i=30..35)
{0xFFCE18A1+0x40*i} RLN{i}LUOR1 (i=30..35)
{0xFFCE18A4+0x40*i} RLN{i}LUTDR 16-bit (i=30..35)
{0xFFCE18A4+0x40*i} RLN{i}LUTDRL (i=30..35)
{0xFFCE18A5+0x40*i} RLN{i}LUTDRH (i=30..35)
{0xFFCE18A6+0x40*i} RLN{i}LURDR 16-bit ro (i=30..35)
{0xFFCE18A6+0x40*i} RLN{i}LURDRL ro (i=30..35)
{0xFFCE18A7+0x40*i} RLN{i}LURDRH ro (i=30..35)
{0xFFCE18A8+0x40*i} RLN{i}LUWTDR 16-bit (i=30..35)
{0xFFCE18A8+0x40*i} RLN{i}LUWTDRL (i=30..35)
{0xFFCE18A9+0x40*i} RLN{i}LUWTDRH (i=30..35)
{0xFFCE2057+i} RLN31LDBR{i} (i=1..8)
{0xFFCE2097+i} RLN32LDBR{i} (i=1..8)
{0xFFCE20D7+i} RLN33LDBR{i} (i=1..8)
{0xFFCE2117+i} RLN34LDBR{i} (i=1..8)
{0xFFCE2157+i} RLN35LDBR{i} (i=1..8)
{0xFFD00000+0x10*i} RSCAN0C{i}CFG 32-bit (i=0..5)
{0xFFD00000+0x10*i} RSCAN0C{i}CFGL 16-bit (i=0..5)
{0xFFD00000+0x10*i} RSCAN0C{i}CFGLL (i=0..5)
{0xFFD00001+0x10*i} RSCAN0C{i}CFGLH (i=0..5)
{0xFFD00002+0x10*i} RSCAN0C{i}CFGH 16-bit (i=0..5)
{0xFFD00002+0x10*i} RSCAN0C{i}CFGHL (i=0..5)
{0xFFD00003+0x10*i} RSCAN0C{i}CFGHH (i=0..5)
{0xFFD00004+0x10*i} RSCAN0C{i}CTR 32-bit (i=0..5)
{0xFFD00004+0x10*i} RSCAN0C{i}CTRL 16-bit (i=0..5)
{0xFFD00004+0x10*i} RSCAN0C{i}CTRLL (i=0..5)
{0xFFD00005+0x10*i} RSCAN0C{i}CTRLH (i=0..5)
{0xFFD00006+0x10*i} RSCAN0C{i}CTRH 16-bit (i=0..5)
{0xFFD00006+0x10*i} RSCAN0C{i}CTRHL (i=0..5)
{0xFFD00007+0x10*i} RSCAN0C{i}CTRHH (i=0..5)
{0xFFD00008+0x10*i} RSCAN0C{i}STS 32-bit ro (i=0..5)
{0xFFD00008+0x10*i} RSCAN0C{i}STSL 16-bit ro (i=0..5)
{0xFFD00008+0x10*i} RSCAN0C{i}STSLL ro (i=0..5)
{0xFFD0000A+0x10*i} RSCAN0C{i}STSH 16-bit ro (i=0..5)
{0xFFD0000A+0x10*i} RSCAN0C{i}STSHL ro (i=0..5)
{0xFFD0000B+0x10*i} RSCAN0C{i}STSHH ro (i=0..5)
{0xFFD0000C+0x10*i} RSCAN0C{i}ERFL 32-bit (i=0..5)
{0xFFD0000C+0x10*i} RSCAN0C{i}ERFLL 16-bit (i=0..5)
{0xFFD0000C+0x10*i} RSCAN0C{i}ERFLLL (i=0..5)
{0xFFD0000D+0x10*i} RSCAN0C{i}ERFLLH (i=0..5)
{0xFFD0000E+0x10*i} RSCAN0C{i}ERFLH 16-bit ro (i=0..5)
{0xFFD0000E+0x10*i} RSCAN0C{i}ERFLHL ro (i=0..5)
{0xFFD0000F+0x10*i} RSCAN0C{i}ERFLHH ro (i=0..5)
0xFFD00084 RSCAN0GCFG 32-bit
0xFFD00084 RSCAN0GCFGL 16-bit
0xFFD00084 RSCAN0GCFGLL
0xFFD00085 RSCAN0GCFGLH
0xFFD00086 RSCAN0GCFGH 16-bit
0xFFD00086 RSCAN0GCFGHL
0xFFD00087 RSCAN0GCFGHH
0xFFD00088 RSCAN0GCTR 32-bit
0xFFD00088 RSCAN0GCTRL 16-bit
0xFFD00088 RSCAN0GCTRLL
0xFFD00089 RSCAN0GCTRLH
0xFFD0008A RSCAN0GCTRH 16-bit
0xFFD0008A RSCAN0GCTRHL
0xFFD0008C RSCAN0GSTS 32-bit ro
0xFFD0008C RSCAN0GSTSL 16-bit ro
0xFFD0008C RSCAN0GSTSLL ro
0xFFD00090 RSCAN0GERFL 32-bit
0xFFD00090 RSCAN0GERFLL 16-bit
0xFFD00090 RSCAN0GERFLLL
0xFFD00094 RSCAN0GTSC 32-bit ro
0xFFD00094 RSCAN0GTSCL 16-bit ro
0xFFD00098 RSCAN0GAFLECTR 32-bit
0xFFD00098 RSCAN0GAFLECTRL 16-bit
0xFFD00098 RSCAN0GAFLECTRLL
0xFFD00099 RSCAN0GAFLECTRLH
0xFFD0009C RSCAN0GAFLCFG0 32-bit
0xFFD0009C RSCAN0GAFLCFG0L 16-bit
0xFFD0009C RSCAN0GAFLCFG0LL
0xFFD0009D RSCAN0GAFLCFG0LH
0xFFD0009E RSCAN0GAFLCFG0H 16-bit
0xFFD0009E RSCAN0GAFLCFG0HL
0xFFD0009F RSCAN0GAFLCFG0HH
0xFFD000A0 RSCAN0GAFLCFG1 32-bit
0xFFD000A2 RSCAN0GAFLCFG1H 16-bit
0xFFD000A2 RSCAN0GAFLCFG1HL
0xFFD000A3 RSCAN0GAFLCFG1HH
0xFFD000A4 RSCAN0RMNB 32-bit
0xFFD000A4 RSCAN0RMNBL 16-bit
0xFFD000A4 RSCAN0RMNBLL
{0xFFD000A8+4i} RSCAN0RMND{i} 32-bit (i=0..2)
{0xFFD000A8+4i} RSCAN0RMND{i}L 16-bit (i=0..2)
{0xFFD000A8+4i} RSCAN0RMND{i}LL (i=0..2)
{0xFFD000A9+4i} RSCAN0RMND{i}LH (i=0..2)
{0xFFD000AA+4i} RSCAN0RMND{i}H 16-bit (i=0..2)
{0xFFD000AA+4i} RSCAN0RMND{i}HL (i=0..2)
{0xFFD000AB+4i} RSCAN0RMND{i}HH (i=0..2)
{0xFFD000B8+4i} RSCAN0RFCC{i} 32-bit (i=0..7)
{0xFFD000B8+4i} RSCAN0RFCC{i}L 16-bit (i=0..7)
{0xFFD000B8+4i} RSCAN0RFCC{i}LL (i=0..7)
{0xFFD000B9+4i} RSCAN0RFCC{i}LH (i=0..7)
{0xFFD000D8+4i} RSCAN0RFSTS{i} 32-bit (i=0..7)
{0xFFD000D8+4i} RSCAN0RFSTS{i}L 16-bit (i=0..7)
{0xFFD000D8+4i} RSCAN0RFSTS{i}LL (i=0..7)
{0xFFD000D9+4i} RSCAN0RFSTS{i}LH ro (i=0..7)
{0xFFD000F8+4i} RSCAN0RFPCTR{i} 32-bit wo (i=0..7)
{0xFFD000F8+4i} RSCAN0RFPCTR{i}L 16-bit wo (i=0..7)
{0xFFD000F8+4i} RSCAN0RFPCTR{i}LL wo (i=0..7)
{0xFFD00118+4i} RSCAN0CFCC{i} 32-bit (i=0..17)
{0xFFD00118+4i} RSCAN0CFCC{i}L 16-bit (i=0..17)
{0xFFD00118+4i} RSCAN0CFCC{i}LL (i=0..17)
{0xFFD00119+4i} RSCAN0CFCC{i}LH (i=0..17)
{0xFFD0011A+4i} RSCAN0CFCC{i}H 16-bit (i=0..17)
{0xFFD0011A+4i} RSCAN0CFCC{i}HL (i=0..17)
{0xFFD0011B+4i} RSCAN0CFCC{i}HH (i=0..17)
{0xFFD00178+4i} RSCAN0CFSTS{i} 32-bit (i=0..17)
{0xFFD00178+4i} RSCAN0CFSTS{i}L 16-bit (i=0..17)
{0xFFD00178+4i} RSCAN0CFSTS{i}LL (i=0..17)
{0xFFD00179+4i} RSCAN0CFSTS{i}LH ro (i=0..17)
{0xFFD001D8+4i} RSCAN0CFPCTR{i} 32-bit wo (i=0..17)
{0xFFD001D8+4i} RSCAN0CFPCTR{i}L 16-bit wo (i=0..17)
{0xFFD001D8+4i} RSCAN0CFPCTR{i}LL wo (i=0..17)
0xFFD00238 RSCAN0FESTS 32-bit ro
0xFFD00238 RSCAN0FESTSL 16-bit ro
0xFFD00238 RSCAN0FESTSLL ro
0xFFD00239 RSCAN0FESTSLH ro
0xFFD0023A RSCAN0FESTSH 16-bit ro
0xFFD0023A RSCAN0FESTSHL ro
0xFFD0023B RSCAN0FESTSHH ro
0xFFD0023C RSCAN0FFSTS 32-bit ro
0xFFD0023C RSCAN0FFSTSL 16-bit ro
0xFFD0023C RSCAN0FFSTSLL ro
0xFFD0023D RSCAN0FFSTSLH ro
0xFFD0023E RSCAN0FFSTSH 16-bit ro
0xFFD0023E RSCAN0FFSTSHL ro
0xFFD0023F RSCAN0FFSTSHH ro
0xFFD00240 RSCAN0FMSTS 32-bit ro
0xFFD00240 RSCAN0FMSTSL 16-bit ro
0xFFD00240 RSCAN0FMSTSLL ro
0xFFD00241 RSCAN0FMSTSLH ro
0xFFD00242 RSCAN0FMSTSH 16-bit ro
0xFFD00242 RSCAN0FMSTSHL ro
0xFFD00243 RSCAN0FMSTSHH ro
0xFFD00244 RSCAN0RFISTS 32-bit ro
0xFFD00244 RSCAN0RFISTSL 16-bit ro
0xFFD00244 RSCAN0RFISTSLL ro
0xFFD00248 RSCAN0CFRISTS 32-bit ro
0xFFD00248 RSCAN0CFRISTSL 16-bit ro
0xFFD00248 RSCAN0CFRISTSLL ro
0xFFD00249 RSCAN0CFRISTSLH ro
0xFFD0024A RSCAN0CFRISTSH 16-bit ro
0xFFD0024A RSCAN0CFRISTSHL ro
0xFFD0024C RSCAN0CFTISTS 32-bit ro
0xFFD0024C RSCAN0CFTISTSL 16-bit ro
0xFFD0024C RSCAN0CFTISTSLL ro
0xFFD0024D RSCAN0CFTISTSLH ro
0xFFD0024E RSCAN0CFTISTSH 16-bit ro
0xFFD0024E RSCAN0CFTISTSHL ro
{0xFFD00250+i} RSCAN0TMC{i} (i=0..95)
{0xFFD002D0+i} RSCAN0TMSTS{i} (i=0..95)
{0xFFD00350+4i} RSCAN0TMTRSTS{i} 32-bit ro (i=0..2)
{0xFFD00350+4i} RSCAN0TMTRSTS{i}L 16-bit ro (i=0..2)
{0xFFD00350+4i} RSCAN0TMTRSTS{i}LL ro (i=0..2)
{0xFFD00351+4i} RSCAN0TMTRSTS{i}LH ro (i=0..2)
{0xFFD00352+4i} RSCAN0TMTRSTS{i}H 16-bit ro (i=0..2)
{0xFFD00352+4i} RSCAN0TMTRSTS{i}HL ro (i=0..2)
{0xFFD00353+4i} RSCAN0TMTRSTS{i}HH ro (i=0..2)
{0xFFD00360+4i} RSCAN0TMTARSTS{i} 32-bit ro (i=0..2)
{0xFFD00360+4i} RSCAN0TMTARSTS{i}L 16-bit ro (i=0..2)
{0xFFD00360+4i} RSCAN0TMTARSTS{i}LL ro (i=0..2)
{0xFFD00361+4i} RSCAN0TMTARSTS{i}LH ro (i=0..2)
{0xFFD00362+4i} RSCAN0TMTARSTS{i}H 16-bit ro (i=0..2)
{0xFFD00362+4i} RSCAN0TMTARSTS{i}HL ro (i=0..2)
{0xFFD00363+4i} RSCAN0TMTARSTS{i}HH ro (i=0..2)
{0xFFD00370+4i} RSCAN0TMTCSTS{i} 32-bit ro (i=0..2)
{0xFFD00370+4i} RSCAN0TMTCSTS{i}L 16-bit ro (i=0..2)
{0xFFD00370+4i} RSCAN0TMTCSTS{i}LL ro (i=0..2)
{0xFFD00371+4i} RSCAN0TMTCSTS{i}LH ro (i=0..2)
{0xFFD00372+4i} RSCAN0TMTCSTS{i}H 16-bit ro (i=0..2)
{0xFFD00372+4i} RSCAN0TMTCSTS{i}HL ro (i=0..2)
{0xFFD00373+4i} RSCAN0TMTCSTS{i}HH ro (i=0..2)
{0xFFD00380+4i} RSCAN0TMTASTS{i} 32-bit ro (i=0..2)
{0xFFD00380+4i} RSCAN0TMTASTS{i}L 16-bit ro (i=0..2)
{0xFFD00380+4i} RSCAN0TMTASTS{i}LL ro (i=0..2)
{0xFFD00381+4i} RSCAN0TMTASTS{i}LH ro (i=0..2)
{0xFFD00382+4i} RSCAN0TMTASTS{i}H 16-bit ro (i=0..2)
{0xFFD00382+4i} RSCAN0TMTASTS{i}HL ro (i=0..2)
{0xFFD00383+4i} RSCAN0TMTASTS{i}HH ro (i=0..2)
{0xFFD00390+4i} RSCAN0TMIEC{i} 32-bit (i=0..2)
{0xFFD00390+4i} RSCAN0TMIEC{i}L 16-bit (i=0..2)
{0xFFD00390+4i} RSCAN0TMIEC{i}LL (i=0..2)
{0xFFD00391+4i} RSCAN0TMIEC{i}LH (i=0..2)
{0xFFD00392+4i} RSCAN0TMIEC{i}H 16-bit (i=0..2)
{0xFFD00392+4i} RSCAN0TMIEC{i}HL (i=0..2)
{0xFFD00393+4i} RSCAN0TMIEC{i}HH (i=0..2)
{0xFFD003A0+4i} RSCAN0TXQCC{i} 32-bit (i=0..5)
{0xFFD003A0+4i} RSCAN0TXQCC{i}L 16-bit (i=0..5)
{0xFFD003A0+4i} RSCAN0TXQCC{i}LL (i=0..5)
{0xFFD003A1+4i} RSCAN0TXQCC{i}LH (i=0..5)
{0xFFD003C0+4i} RSCAN0TXQSTS{i} 32-bit (i=0..5)
{0xFFD003C0+4i} RSCAN0TXQSTS{i}L 16-bit (i=0..5)
{0xFFD003C0+4i} RSCAN0TXQSTS{i}LL (i=0..5)
{0xFFD003E0+4i} RSCAN0TXQPCTR{i} 32-bit wo (i=0..5)
{0xFFD003E0+4i} RSCAN0TXQPCTR{i}L 16-bit wo (i=0..5)
{0xFFD003E0+4i} RSCAN0TXQPCTR{i}LL wo (i=0..5)
{0xFFD00400+4i} RSCAN0THLCC{i} 32-bit (i=0..5)
{0xFFD00400+4i} RSCAN0THLCC{i}L 16-bit (i=0..5)
{0xFFD00400+4i} RSCAN0THLCC{i}LL (i=0..5)
{0xFFD00401+4i} RSCAN0THLCC{i}LH (i=0..5)
{0xFFD00420+4i} RSCAN0THLSTS{i} 32-bit (i=0..5)
{0xFFD00420+4i} RSCAN0THLSTS{i}L 16-bit (i=0..5)
{0xFFD00420+4i} RSCAN0THLSTS{i}LL (i=0..5)
{0xFFD00421+4i} RSCAN0THLSTS{i}LH ro (i=0..5)
{0xFFD00440+4i} RSCAN0THLPCTR{i} 32-bit wo (i=0..5)
{0xFFD00440+4i} RSCAN0THLPCTR{i}L 16-bit wo (i=0..5)
{0xFFD00440+4i} RSCAN0THLPCTR{i}LL wo (i=0..5)
0xFFD00460 RSCAN0GTINTSTS0 32-bit ro
0xFFD00460 RSCAN0GTINTSTS0L 16-bit ro
0xFFD00460 RSCAN0GTINTSTS0LL ro
0xFFD00461 RSCAN0GTINTSTS0LH ro
0xFFD00462 RSCAN0GTINTSTS0H 16-bit ro
0xFFD00462 RSCAN0GTINTSTS0HL ro
0xFFD00463 RSCAN0GTINTSTS0HH ro
0xFFD00464 RSCAN0GTINTSTS1 32-bit ro
0xFFD00464 RSCAN0GTINTSTS1L 16-bit ro
0xFFD00464 RSCAN0GTINTSTS1LL ro
0xFFD00465 RSCAN0GTINTSTS1LH ro
0xFFD00468 RSCAN0GTSTCFG 32-bit
0xFFD00468 RSCAN0GTSTCFGL 16-bit
0xFFD00468 RSCAN0GTSTCFGLL
0xFFD0046A RSCAN0GTSTCFGH 16-bit
0xFFD0046A RSCAN0GTSTCFGHL
0xFFD0046C RSCAN0GTSTCTR 32-bit
0xFFD0046C RSCAN0GTSTCTRL 16-bit
0xFFD0046C RSCAN0GTSTCTRLL
0xFFD0047C RSCAN0GLOCKK 32-bit wo
0xFFD0047C RSCAN0GLOCKKL 16-bit wo
{0xFFD00500+0x10*i} RSCAN0GAFLID{i} 32-bit (i=0..15)
{0xFFD00500+0x10*i} RSCAN0GAFLID{i}L 16-bit (i=0..15)
{0xFFD00500+0x10*i} RSCAN0GAFLID{i}LL (i=0..15)
{0xFFD00501+0x10*i} RSCAN0GAFLID{i}LH (i=0..15)
{0xFFD00502+0x10*i} RSCAN0GAFLID{i}H 16-bit (i=0..15)
{0xFFD00502+0x10*i} RSCAN0GAFLID{i}HL (i=0..15)
{0xFFD00503+0x10*i} RSCAN0GAFLID{i}HH (i=0..15)
{0xFFD00504+0x10*i} RSCAN0GAFLM{i} 32-bit (i=0..15)
{0xFFD00504+0x10*i} RSCAN0GAFLM{i}L 16-bit (i=0..15)
